# ATtiny88 device description
Architecture: AVR8; Family: tinyAVR
Registers are 8-bit, access not given, no defined reset value unless marked. A register's access mark holds for its fields unless they carry their own. Offsets are from the block's base; [hi:lo] are bit positions; 'fields as' and 'values as' point back to an identical list.

## EXINT — External Interrupts
Instances: EXINT 0x00
0x3B PCIFR — Pin Change Interrupt Flag Register
  [3:0] PCIF — Pin Change Interrupt Flags
0x3C EIFR — External Interrupt Flag Register
  [1:0] INTF — External Interrupt Flags
0x3D EIMSK — External Interrupt Mask Register
  [1:0] INT — External Interrupt Request 1 Enable
0x68 PCICR
  [3:0] PCIE
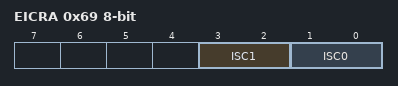
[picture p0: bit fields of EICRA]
0x69 EICRA — External Interrupt Control Register
  [3:2] ISC1 — External Interrupt Sense Control 1 Bits
    0=Low Level of INTX; 1=Any Logical Change in INTX; 2=Falling Edge of INTX; 3=Rising Edge of INTX
  [1:0] ISC0 — External Interrupt Sense Control 0 Bits
    values as ISC1
0x6A PCMSK3 — Pin Change Mask Register 3
  [3:0] PCINT (bit 24 of the value upward) — Pin Change Enable Masks
0x6B PCMSK0 — Pin Change Mask Register 0
  [7:0] PCINT — Pin Change Enable Masks
0x6C PCMSK1 — Pin Change Mask Register 1
  [7:0] PCINT (bit 8 of the value upward) — Pin Change Enable Masks
0x6D PCMSK2 — Pin Change Mask Register 2
  [7:0] PCINT (bit 16 of the value upward) — Pin Change Enable Masks

## TC0 (TC8 module) — Timer/Counter, 8-bit
Instances: TC0 0x00
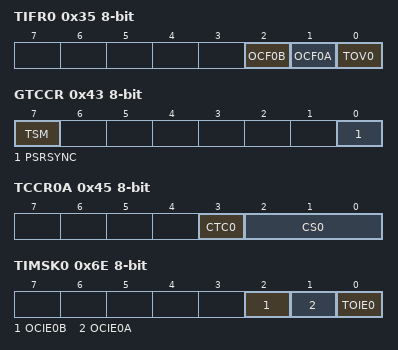
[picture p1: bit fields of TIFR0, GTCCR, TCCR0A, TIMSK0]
0x35 TIFR0 — Timer/Counter0 Interrupt Flag register
  [2] OCF0B — Timer/Counter0 Output Compare Flag 0B
  [1] OCF0A — Timer/Counter0 Output Compare Flag 0A
  [0] TOV0 — Timer/Counter0 Overflow Flag
0x43 GTCCR — General Timer/Counter Control Register
  [7] TSM — Timer/Counter Synchronization Mode
  [0] PSRSYNC — Prescaler Reset Timer/Counter1 and Timer/Counter0
0x45 TCCR0A — Timer/Counter Control Register A
  [3] CTC0 — Clear Timer on Compare Match
  [2:0] CS0 — Clock Select
    0=No Clock Source (Stopped); 1=Running, No Prescaling; 2=Running, CLK/8; 3=Running, CLK/64; 4=Running, CLK/256; 5=Running, CLK/1024; 6=Running, ExtClk Tx Falling Edge; 7=Running, ExtClk Tx Rising Edge
0x46 TCNT0 — Timer/Counter0
0x47 OCR0A — Timer/Counter0 Output Compare Register
0x48 OCR0B — Timer/Counter0 Output Compare Register
0x6E TIMSK0 — Timer/Counter0 Interrupt Mask Register
  [2] OCIE0B — Timer/Counter0 Output Compare Match B Interrupt Enable
  [1] OCIE0A — Timer/Counter0 Output Compare Match A Interrupt Enable
  [0] TOIE0 — Timer/Counter0 Overflow Interrupt Enable

## CPU — CPU Registers
Instances: CPU 0x00
Parameters: CORE_VERSION=V2, NEW_INSTRUCTIONS=lpm rd,z+
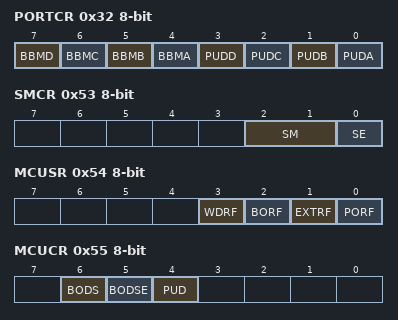
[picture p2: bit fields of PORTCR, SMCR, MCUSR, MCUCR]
0x32 PORTCR — Port Configuration Register
  [7] BBMD, [6] BBMC, [5] BBMB, [4] BBMA, [3] PUDD, [2] PUDC, [1] PUDB, [0] PUDA
0x3E GPIOR0 — General Purpose I/O Register 0
0x4A GPIOR1 — General Purpose I/O Register 1
0x4B GPIOR2 — General Purpose I/O Register 2
0x53 SMCR — Sleep Mode Control Register
  [2:1] SM — Sleep Mode
    0=IDLE; 1=ADC (ADC Noise Reduction (If Available)); 2=PDOWN (Power Down); 3=PSAVE (Power Save)
  [0] SE — Sleep Enable
0x54 MCUSR — MCU Status Register
  [3] WDRF — Watchdog Reset Flag
  [2] BORF — Brown-out Reset Flag
  [1] EXTRF — External Reset Flag
  [0] PORF — Power-on reset flag
0x55 MCUCR — MCU Control Register
  [6] BODS — BOD Sleep
  [5] BODSE — BOD Sleep Enable
  [4] PUD — Pull-up Disable
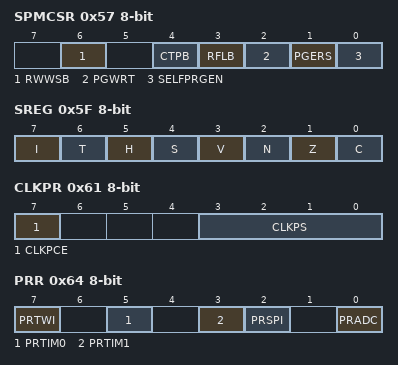
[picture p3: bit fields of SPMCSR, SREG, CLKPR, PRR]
0x57 SPMCSR — Store Program Memory Control Register
  [6] RWWSB — Read-While-Write Section Busy
  [4] CTPB — Clear Temporary Page Buffer
  [3] RFLB — Read Fuse and Lock Bits
  [2] PGWRT — Page Write
  [1] PGERS — Page Erase
  [0] SELFPRGEN — Self Programming Enable
0x5D SPL — Stack Pointer Low
0x5E SPH bits used 1:0 — Stack Pointer High
0x5F SREG — Status Register
  [7] I — Global Interrupt Enable
  [6] T — Bit Copy Storage
  [5] H — Half Carry Flag
  [4] S — Sign Bit
  [3] V — Two's Complement Overflow Flag
  [2] N — Negative Flag
  [1] Z — Zero Flag
  [0] C — Carry Flag
0x61 CLKPR — Clock Prescale Register
  [7] CLKPCE — Clock Prescaler Change Enable
  [3:0] CLKPS — Clock Prescaler Select Bits
    0=1; 1=2; 2=4; 3=8; 4=16; 5=32; 6=64; 7=128; 8=256
0x64 PRR — Power Reduction Register
  [7] PRTWI — Power Reduction TWI
  [5] PRTIM0 — Power Reduction Timer/Counter0
  [3] PRTIM1 — Power Reduction Timer/Counter1
  [2] PRSPI — Power Reduction Serial Peripheral Interface
  [0] PRADC — Power Reduction ADC
0x66 OSCCAL — Oscillator Calibration Value
  [7:0] OSCCAL — Oscillator Calibration
Value list OSCCAL_VALUE_ADDRESSES: 0=8_0_MHz

## EEPROM
Instances: EEPROM 0x00
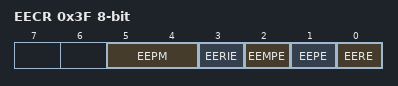
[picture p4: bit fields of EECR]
0x3F EECR — EEPROM Control Register
  [5:4] EEPM — EEPROM Programming Mode Bits
    0=Erase and Write in one operation; 1=Erase Only; 2=Write Only
  [3] EERIE — EEPROM Ready Interrupt Enable
  [2] EEMPE — EEPROM Master Write Enable
  [1] EEPE — EEPROM Write Enable
  [0] EERE — EEPROM Read Enable
0x40 EEDR — EEPROM Data Register
0x41 EEARL bits used 5:0 — EEPROM Address Register Low Byte
